VERSION ""

NS_ :

BS_:

BU_: EBCM NEO CAM RADAR PCM EPS VSA SCM BDY XXX EPB

BO_ 57 XXX_1: 3 XXX

BO_ 148 XXX_2: 8 XXX

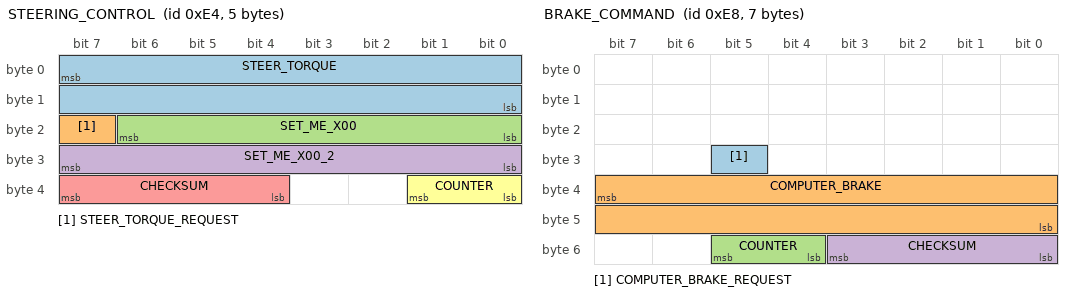
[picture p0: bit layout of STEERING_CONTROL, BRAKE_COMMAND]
BO_ 228 STEERING_CONTROL: 5 NEO
 SG_ STEER_TORQUE : 7|16@0- (1,0) [-3840|3840] ""  EPS
 SG_ STEER_TORQUE_REQUEST : 23|1@0+ (1,0) [0|1] ""  EPS
 SG_ SET_ME_X00 : 22|7@0+ (1,0) [0|127] ""  EPS
 SG_ SET_ME_X00_2 : 31|8@0+ (1,0) [0|0] ""  EPS
 SG_ CHECKSUM : 39|4@0+ (1,0) [0|15] ""  EPS
 SG_ COUNTER : 33|2@0+ (1,0) [0|3] ""  EPS

BO_ 232 BRAKE_COMMAND: 7 NEO
 SG_ CAR_SPEED : 3|10@0- (1,0)  [1,0]
 SG_ XXX : 8|1@0- (1,0)  [1,0]
 SG_ COMPUTER_BRAKE_REQUEST : 29|1@0+ (1,0) [0|0] "" EBCM
 SG_ COMPUTER_BRAKE : 39|16@0+ (1,0) [0|0] "" EBCM
 SG_ COUNTER : 53|2@0+ (1,0) [0|3] ""  BDY
 SG_ CHECKSUM : 51|4@0+ (1,0) [0|3] ""  BDY

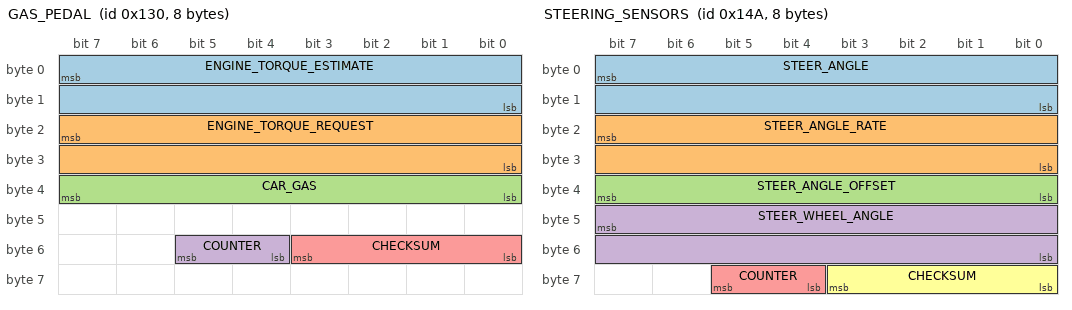
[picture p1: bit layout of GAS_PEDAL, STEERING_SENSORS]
BO_ 304 GAS_PEDAL: 8 PCM
 SG_ ENGINE_TORQUE_ESTIMATE : 7|16@0- (1,0) [-1000|1000] "Nm"  NEO
 SG_ ENGINE_TORQUE_REQUEST : 23|16@0- (1,0) [-1000|1000] "Nm"  NEO
 SG_ CAR_GAS : 39|8@0+ (1,0) [0|255] ""  NEO
 SG_ COUNTER : 53|2@0+ (1,0) [0|3] ""  NEO
 SG_ CHECKSUM : 51|4@0+ (1,0) [0|3] ""  NEO

BO_ 330 STEERING_SENSORS: 8 EPS
 SG_ STEER_ANGLE : 7|16@0- (-0.1,0) [-500|500] "deg"  NEO
 SG_ STEER_ANGLE_RATE : 23|16@0- (-1,0) [-3000|3000] "deg/s"  NEO
 SG_ STEER_ANGLE_OFFSET : 39|8@0- (-0.1,0) [-128|127] "deg"  NEO
 SG_ STEER_WHEEL_ANGLE : 47|16@0- (-0.1,0) [-500|500] "deg"  NEO
 SG_ COUNTER : 61|2@0+ (1,0) [0|3] ""  NEO
 SG_ CHECKSUM : 59|4@0+ (1,0) [0|3] ""  NEO

BO_ 340 XXX_4: 8 XXX

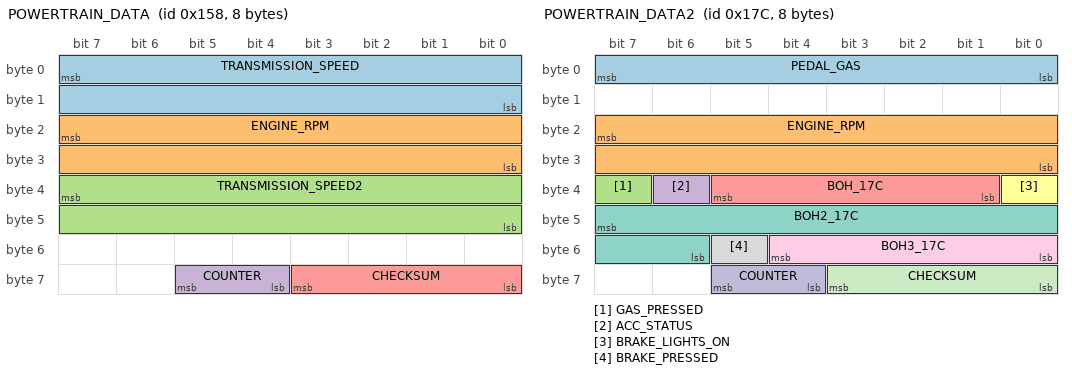
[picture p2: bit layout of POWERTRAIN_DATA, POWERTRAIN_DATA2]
BO_ 344 POWERTRAIN_DATA: 8 PCM
 SG_ TRANSMISSION_SPEED : 7|16@0+ (0.002759506,0) [0|70] "m/s"  NEO
 SG_ ENGINE_RPM : 23|16@0+ (1,0) [0|15000] "rpm"  NEO
 SG_ TRANSMISSION_SPEED2 : 39|16@0+ (0.002759506,0) [0|70] "m/s"  NEO
 SG_ COUNTER : 61|2@0+ (1,0) [0|3] ""  NEO
 SG_ CHECKSUM : 59|4@0+ (1,0) [0|3] ""  NEO

BO_ 380 POWERTRAIN_DATA2: 8 PCM
 SG_ PEDAL_GAS : 7|8@0+ (1,0) [0|255] ""  NEO
 SG_ ENGINE_RPM : 23|16@0+ (1,0) [0|15000] "rpm"  NEO
 SG_ GAS_PRESSED : 39|1@0+ (1,0) [0|1] ""  NEO
 SG_ ACC_STATUS : 38|1@0+ (1,0) [0|1] "rpm"  NEO
 SG_ BOH_17C : 37|5@0+ (1,0) [0|1] "rpm"  NEO
 SG_ BRAKE_LIGHTS_ON : 32|1@0+ (1,0) [0|1] "rpm"  NEO
 SG_ BOH2_17C : 47|10@0+ (1,0) [0|1] "rpm"  NEO
 SG_ BRAKE_PRESSED : 53|1@0+ (1,0) [0|1] ""  NEO
 SG_ BOH3_17C : 52|5@0+ (1,0) [0|1] "rpm"  NEO
 SG_ COUNTER : 61|2@0+ (1,0) [0|3] ""  NEO
 SG_ CHECKSUM : 59|4@0+ (1,0) [0|3] ""  NEO

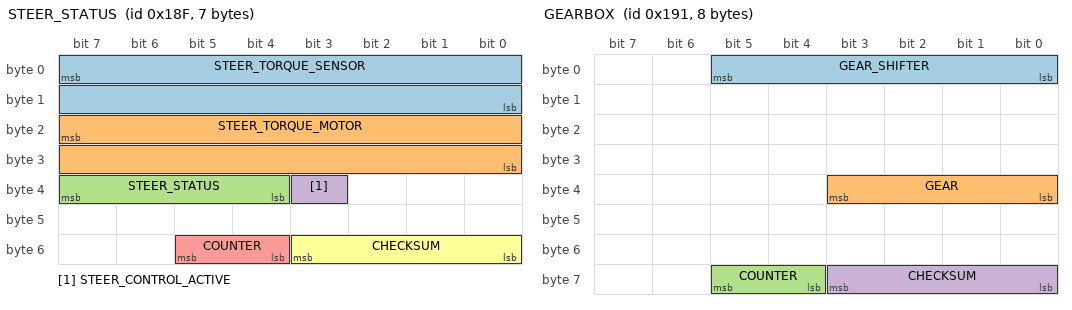
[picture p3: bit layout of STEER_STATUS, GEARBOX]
BO_ 399 STEER_STATUS: 7 EPS
 SG_ STEER_TORQUE_SENSOR : 7|16@0- (1,0) [-31000|31000] "tbd"  NEO
 SG_ STEER_TORQUE_MOTOR : 23|16@0- (1,0) [-31000|31000] "tbd"  NEO
 SG_ STEER_STATUS : 39|4@0+ (1,0) [0|15] ""  NEO
 SG_ STEER_CONTROL_ACTIVE : 35|1@0+ (1,0) [0|1] ""  NEO
 SG_ COUNTER : 53|2@0+ (1,0) [0|3] ""  NEO
 SG_ CHECKSUM : 51|4@0+ (1,0) [0|3] ""  NEO

BO_ 401 GEARBOX: 8 PCM
 SG_ GEAR_SHIFTER : 5|6@0+ (1,0) [0|63] ""  NEO
 SG_ GEAR : 35|4@0+ (1,0) [0|15] ""  NEO
 SG_ COUNTER : 61|2@0+ (1,0) [0|3] ""  NEO
 SG_ CHECKSUM : 59|4@0+ (1,0) [0|3] ""  NEO

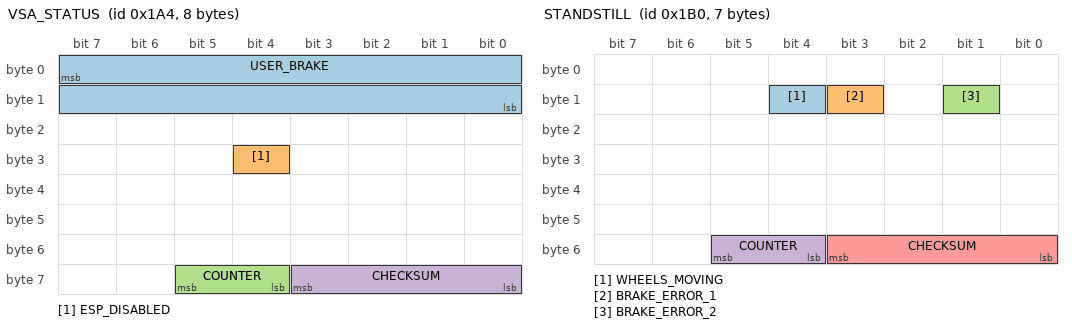
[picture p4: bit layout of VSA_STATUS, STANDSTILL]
BO_ 420 VSA_STATUS: 8 VSA
 SG_ USER_BRAKE : 7|16@0+ (0.015625,-103) [0|1000] ""  NEO
 SG_ ESP_DISABLED : 28|1@0+ (1,0) [0|1] ""  NEO
 SG_ COUNTER : 61|2@0+ (1,0) [0|3] ""  NEO
 SG_ CHECKSUM : 59|4@0+ (1,0) [0|3] ""  NEO

BO_ 427 XXX_5: 3 VSA

BO_ 432 STANDSTILL: 7 VSA
 SG_ WHEELS_MOVING : 12|1@0+ (1,0) [0|1] ""  NEO
 SG_ BRAKE_ERROR_1 : 11|1@0+ (1,0) [0|1] ""  NEO
 SG_ BRAKE_ERROR_2 : 9|1@0+ (1,0) [0|1] ""  NEO
 SG_ COUNTER : 53|2@0+ (1,0) [0|3] ""  NEO
 SG_ CHECKSUM : 51|4@0+ (1,0) [0|3] ""  NEO

BO_ 441 XXX_6: 5 VSA

BO_ 446 XXX_7: 3 VSA

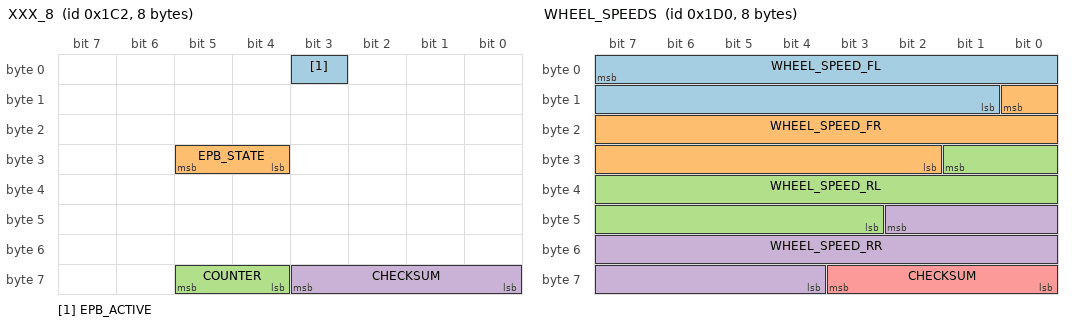
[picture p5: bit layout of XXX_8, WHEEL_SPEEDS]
BO_ 450 XXX_8: 8 EPB
 SG_ EPB_ACTIVE : 3|1@0+ (1,0) [0|1] ""  NEO
 SG_ EPB_STATE : 29|2@0+ (1,0) [0|3] ""  NEO
 SG_ COUNTER : 61|2@0+ (1,0) [0|3] ""  BDY
 SG_ CHECKSUM : 59|4@0+ (1,0) [0|3] ""  BDY

BO_ 464 WHEEL_SPEEDS: 8 VSA
 SG_ WHEEL_SPEED_FL : 7|15@0+ (0.002759506,0) [0|70] "m/s"  NEO
 SG_ WHEEL_SPEED_FR : 8|15@0+ (0.002759506,0) [0|70] "m/s"  NEO
 SG_ WHEEL_SPEED_RL : 25|15@0+ (0.002759506,0) [0|70] "m/s"  NEO
 SG_ WHEEL_SPEED_RR : 42|15@0+ (0.002759506,0) [0|70] "m/s"  NEO
 SG_ CHECKSUM : 59|4@0+ (1,0) [0|3] ""  NEO

BO_ 474 XXX_9: 8 XXX

BO_ 477 XXX_10: 8 XXX

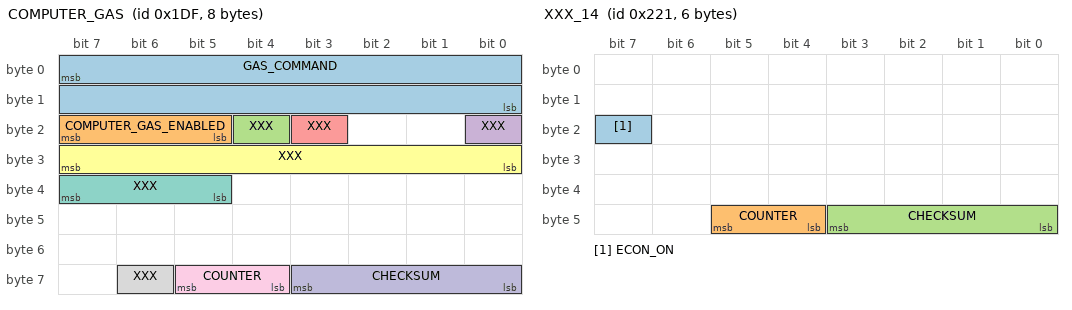
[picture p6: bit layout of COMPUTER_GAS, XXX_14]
BO_ 479 COMPUTER_GAS: 8 NEO
 SG_ GAS_COMMAND : 7|16@0+ (0.253984064,-328) [0|1] "" PCM
 SG_ COMPUTER_GAS_ENABLED : 23|3@0+ (1,0) [0|5] ""  PCM
 SG_ XXX : 20|1@0+ (1,0) [0|1] ""  XXX
 SG_ XXX : 16|1@0+ (1,0) [0|1] ""  XXX
 SG_ XXX : 19|1@0+ (1,0) [0|1] ""  XXX
 SG_ XXX : 31|8@0+ (1,0) [0|255] ""  XXX
 SG_ XXX : 39|3@0+ (1,0) [0|1] ""  XXX
 SG_ XXX : 62|1@0+ (1,0) [0|1] ""  XXX
 SG_ COUNTER : 61|2@0+ (1,0) [0|3] ""  BDY
 SG_ CHECKSUM : 59|4@0+ (1,0) [0|3] ""  BDY

BO_ 490 XXX_12: 8 XXX

BO_ 495 XXX_13: 8 XXX

BO_ 545 XXX_14: 6 SCM
 SG_ ECON_ON : 23|1@0+ (1,0) [0|1] ""  XXX
 SG_ COUNTER : 45|2@0+ (1,0) [0|3] ""  BDY
 SG_ CHECKSUM : 43|4@0+ (1,0) [0|3] ""  BDY

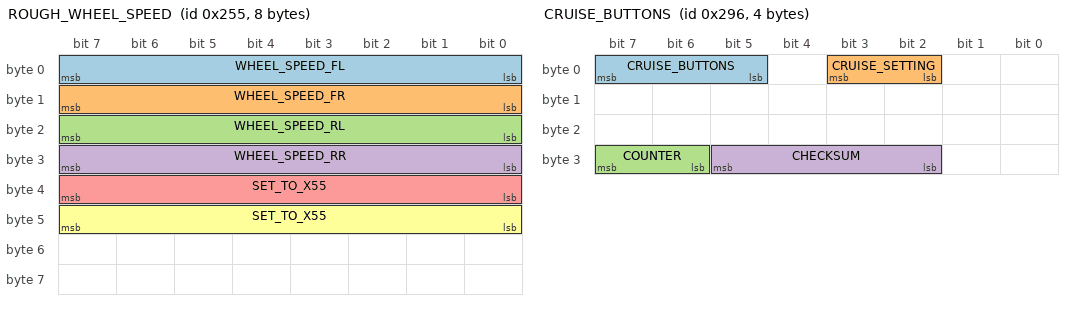
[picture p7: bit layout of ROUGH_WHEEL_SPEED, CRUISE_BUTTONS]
BO_ 597 ROUGH_WHEEL_SPEED: 8 VSA
 SG_ WHEEL_SPEED_FL : 7|8@0+ (1,0) [0|255] "mph"  NEO
 SG_ WHEEL_SPEED_FR : 15|8@0+ (1,0) [0|255] "mph"  NEO
 SG_ WHEEL_SPEED_RL : 23|8@0+ (1,0) [0|255] "mph"  NEO
 SG_ WHEEL_SPEED_RR : 31|8@0+ (1,0) [0|255] "mph"  NEO
 SG_ SET_TO_X55 : 39|8@0+ (1,0) [0|255] ""  NEO
 SG_ SET_TO_X55 : 47|8@0+ (1,0) [0|255] ""  NEO

BO_ 662 CRUISE_BUTTONS: 4 SCM
 SG_ CRUISE_BUTTONS : 7|3@0+ (1,0) [0|7] ""  NEO
 SG_ CRUISE_SETTING : 3|2@0+ (1,0) [0|3] ""  NEO
 SG_ COUNTER : 31|2@0+ (1,0) [0|3] ""  BDY
 SG_ CHECKSUM : 29|4@0+ (1,0) [0|3] ""  BDY

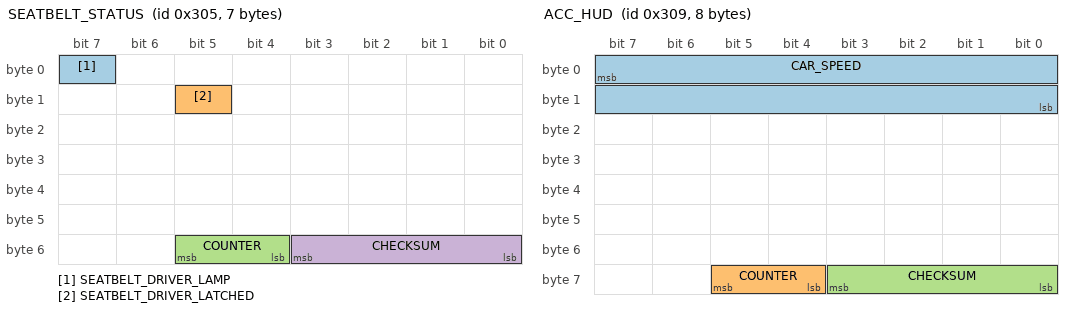
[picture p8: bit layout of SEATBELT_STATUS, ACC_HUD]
BO_ 773 SEATBELT_STATUS: 7 BDY
 SG_ SEATBELT_DRIVER_LAMP : 7|1@0+ (1,0) [0|1] ""  NEO
 SG_ SEATBELT_DRIVER_LATCHED : 13|1@0+ (1,0) [0|1] ""  NEO
 SG_ COUNTER : 53|2@0+ (1,0) [0|3] ""  NEO
 SG_ CHECKSUM : 51|4@0+ (1,0) [0|3] ""  NEO

BO_ 777 ACC_HUD: 8 PCM
 SG_ CAR_SPEED : 7|16@0+ (0.002763889,0) [0|100] "m/s"  BDY
 SG_ COUNTER : 61|2@0+ (1,0) [0|3] ""  BDY
 SG_ CHECKSUM : 59|4@0+ (1,0) [0|3] ""  BDY

BO_ 780 ACC_HUD_2: 8 RADAR
 SG_ ACC_SPEED : 31|8@0+ (1,0) [0|255] "kph"  BDY
 SG_ ACC_PROBLEM : 37|1@0+ (1,0) [0|1] ""  BDY
 SG_ RDMS_STATE : 28|2 @0+ (1,0) [0|1] ""  BDY
 SG_ CMBS_OFF : 35|1@0+ (1,0) [0|1] ""  BDY
 SG_ CMBS_PROBLEM : 34|1@0+ (1,0) [0|1] ""  BDY
 SG_ RADAR_OBSTRUCTED : 33|1@0+ (1,0) [0|1] ""  BDY
 SG_ ACC_ON : 52|1@0+ (1,0) [0|1] ""  BDY
 SG_ COUNTER : 61|2@0+ (1,0) [0|3] ""  BDY
 SG_ CHECKSUM : 59|4@0+ (1,0) [0|3] ""  BDY

BO_ 800 XXX_16: 8 XXX

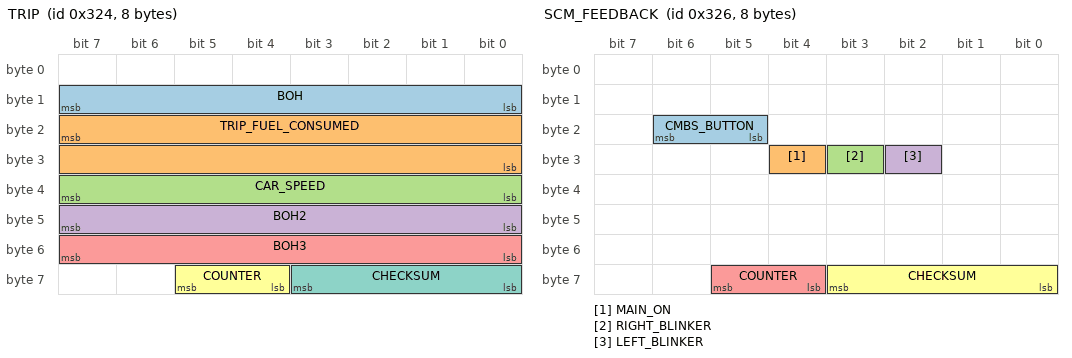
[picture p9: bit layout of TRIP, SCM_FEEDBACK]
BO_ 804 TRIP: 8 PCM
 SG_ BOH : 15|8@0+ (1,0) [0|255] ""  NEO
 SG_ TRIP_FUEL_CONSUMED : 23|16@0+ (1,0) [0|255] ""  NEO
 SG_ CAR_SPEED : 39|8@0+ (1,0) [0|255] ""  NEO
 SG_ BOH2 : 47|8@0- (1,0) [0|255] ""  NEO
 SG_ BOH3 : 55|8@0+ (1,0) [0|255] ""  NEO
 SG_ COUNTER : 61|2@0+ (1,0) [0|3] ""  NEO
 SG_ CHECKSUM : 59|4@0+ (1,0) [0|3] ""  NEO

BO_ 806 SCM_FEEDBACK: 8 SCM
 SG_ CMBS_BUTTON : 22|2@0+ (1,0) [0|3] ""  NEO
 SG_ MAIN_ON : 28|1@0+ (1,0) [0|1] ""  NEO
 SG_ RIGHT_BLINKER : 27|1@0+ (1,0) [0|1] ""  NEO
 SG_ LEFT_BLINKER : 26|1@0+ (1,0) [0|1] ""  NEO
 SG_ COUNTER : 61|2@0+ (1,0) [0|3] ""  BDY
 SG_ CHECKSUM : 59|4@0+ (1,0) [0|3] ""  BDY

BO_ 808 XXX_17: 8 XXX

BO_ 814 XXX_18: 4 XXX

BO_ 829 LKAS_HUD: 5 RADAR
 SG_ CAM_TEMP_HIGH : 7|1@0+ (1,0) [0|255] ""  BDY
 SG_ LKAS_ON : 0|1@0+ (1,0) [0|1] ""  BDY
 SG_ STEERING_REQUIRED : 8|1@0+ (1,0) [0|1] ""  BDY
 SG_ LANE_DEPARTURE : 8|1@0+ (1,0) [0|1] ""  BDY
 SG_ SOLID_LANE_LINES : 10|1@0+ (1,0) [0|1] ""  BDY
 SG_ LANE_LINES_ON : 14|1@0+ (1,0) [0|1] ""  BDY
 SG_ RDM_ON : 20|1@0+ (1,0) [0|1] ""  BDY
 SG_ STEERING_REQ_CHIME : 17|2@0+ (1,0) [0|1] ""  BDY
 SG_ RDMS_STATE : 28|2 @0+ (1,0) [0|1] ""  BDY
 SG_ COUNTER : 37|2@0+ (1,0) [0|3] ""  BDY
 SG_ CHECKSUM : 35|4@0+ (1,0) [0|3] ""  BDY

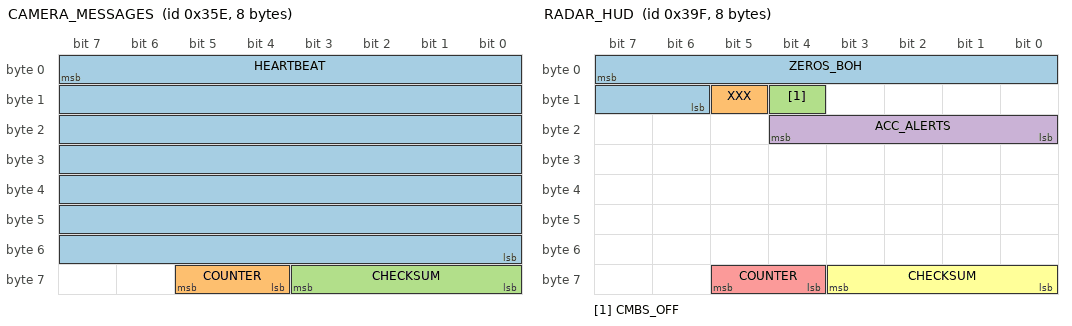
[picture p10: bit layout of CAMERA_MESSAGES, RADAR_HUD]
BO_ 862 CAMERA_MESSAGES: 8 CAM
 SG_ HEARTBEAT : 7|56@0+ (1,0) [0|127] ""  BDY
 SG_ COUNTER : 61|2@0+ (1,0) [0|3] ""  BDY
 SG_ CHECKSUM : 59|4@0+ (1,0) [0|3] ""  BDY

BO_ 884 XXX_20: 8 XXX

BO_ 891 XXX_21: 8 XXX

BO_ 927 RADAR_HUD: 8 RADAR
 SG_ ZEROS_BOH : 7|10@0+ (1,0) [0|127] ""  BDY
 SG_ XXX : 13|1@0+ (1,0) [0|1] "" BDY
 SG_ CMBS_OFF : 12|1@0+ (1,0) [0|1] "" BDY
 SG_ ACC_ALERTS : 20|5@0+ (1,0) [0|1] "" BDY
 SG_ COUNTER : 61|2@0+ (1,0) [0|3] ""  BDY
 SG_ CHECKSUM : 59|4@0+ (1,0) [0|3] ""  BDY

BO_ 929 XXX_23: 8 XXX

BO_ 985 XXX_24: 3 XXX

BO_ 1024 XXX_25: 5 XXX

BO_ 1027 XXX_26: 5 XXX

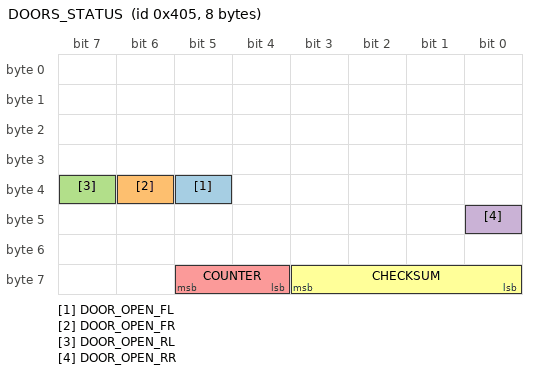
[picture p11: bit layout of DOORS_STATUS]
BO_ 1029 DOORS_STATUS: 8 BDY
 SG_ DOOR_OPEN_FL : 37|1@0+ (1,0) [0|1] ""  NEO
 SG_ DOOR_OPEN_FR : 38|1@0+ (1,0) [0|1] ""  NEO
 SG_ DOOR_OPEN_RL : 39|1@0+ (1,0) [0|1] ""  NEO
 SG_ DOOR_OPEN_RR : 40|1@0+ (1,0) [0|1] ""  NEO
 SG_ COUNTER : 61|2@0+ (1,0) [0|3] ""  NEO
 SG_ CHECKSUM : 59|4@0+ (1,0) [0|3] ""  NEO

BO_ 1036 XXX_27: 8 XXX

BO_ 1039 XXX_28: 8 XXX

BO_ 1108 XXX_29: 8 XXX

BO_ 1302 XXX_30: 8 XXX

BO_ 1322 XXX_31: 5 XXX

BO_ 1361 XXX_32: 5 XXX

BO_ 1365 XXX_33: 5 XXX

BO_ 1424 XXX_34: 5 XXX

BO_ 1600 XXX_35: 5 XXX

BO_ 1601 XXX_36: 8 XXX

BO_ 1618 XXX_37: 5 XXX

BO_ 1633 XXX_38: 8 XXX

BO_ 1670 XXX_39: 8 XXX

BO_TX_BU_ 0xE4 : NEO,RADAR;
BO_TX_BY_ 0xE8 : NEO,RADAR;
BO_TX_BU_ 0x1DF : NEO,RADAR;
BO_TX_BU_ 0x30C : NEO,RADAR;
BO_TX_BU_ 0x33D : NEO,RADAR;
BO_TX_BU_ 0x35E : NEO,CAM;
BO_TX_BU_ 0x39F : NEO,RADAR;
